# M058SAN_v1 register map
File version: 1.0
Registers are 32-bit, read-write, reset 0x0 unless marked. A register's access mark holds for its fields unless they carry their own. Offsets are from the block's base; [hi:lo] are bit positions; {n}, {i} and the like mark numbered series; 'fields as' and 'values as' point back to an identical list.

## I2C0 — I2C Register Map
Base 0x40020000
Same registers: I2C1 0x40120000
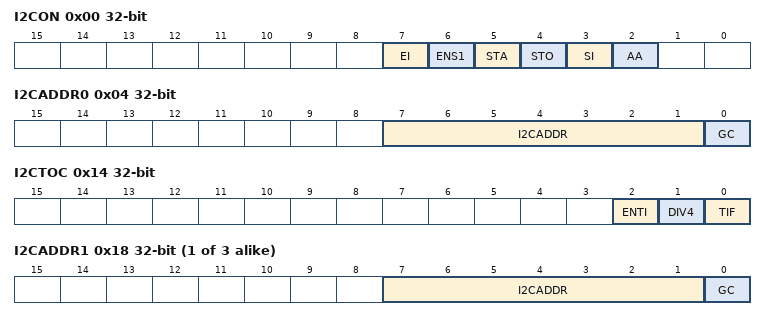
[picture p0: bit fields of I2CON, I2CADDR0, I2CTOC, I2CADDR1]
0x00 I2CON — I2C Control Register
  [7] EI — Enable Interrupt
    0=Disable I2C interrupt; 1=Enable I2C interrupt
  [6] ENS1 — I2C Controller Enable Bit
    0=Disable; 1=Enable
  [5] STA — I2C START Control Bit. Setting STA to logic 1 to enter master mode, the I2C hardware sends a START or repeat START condition to bus when the bus is free.
  [4] STO — I2C STOP Control Bit. In master mode, setting STO to transmit a STOP condition to bus then I2C hardware will check the bus condition if a STOP condition is detected this bit will be cleared by hardware automatically. In a slave mode, setting STO resets I2C hardware to the defined "not addressed" slave mode. This means it is NO LONGER in the slave receiver mode to receive data from the master transmit device.
  [3] SI — I2C Interrupt Flag. When a new I2C state is present in the I2CSTATUS register, the SI flag is set by hardware, and if bit EI (I2CON [7]) is set, the I2C interrupt is requested. SI must be cleared by software. Clear SI is by writing one to this bit.
  [2] AA — Assert Acknowledge Control Bit
0x04 I2CADDR0 — I2C slave Address Register0
  [7:1] I2CADDR — I2C Address Register. The content of this register is irrelevant when I2C is in master mode. In the slave mode, the seven most significant bits must be loaded with the MCU's own address. The I2C hardware will react if either of the address is matched.
  [0] GC — General Call Function
    0=Disable General Call Function; 1=Enable General Call Function
0x08 I2CDAT — I2C DATA Register
  [7:0] I2CDAT — I2C Data Register. Bit [7:0] is located with the 8-bit transferred data of I2C serial port.
0x0C I2CSTATUS ro reset 0xF8
  [7:0] I2CSTATUS — I2C Status Register. The status register of I2C:
0x10 I2CLK — I2C clock divided Register
  [7:0] I2CLK — I2C clock divided Register. Note: The minimum value of I2CLK is 4.
0x14 I2CTOC — I2C Time out control Register
  [2] ENTI — Time-out counter is enabled/disable. When Enable, the 14 bit time-out counter will start counting when SI is clear. Setting flag SI to high will reset counter and re-start up counting after SI is cleared.
    0=Disable; 1=Enable
  [1] DIV4 — Time-Out counter input clock is divided by 4. When Enable, The time-Out period is extend 4 times.
    0=Disable; 1=Enable
  [0] TIF — Time-Out Flag. This bit is set by H/W when I2C time-out happened and it can interrupt CPU if I2C interrupt enable bit (EI) is set to 1. S/W can write 1 to clear this bit.
{0x14+4i} I2CADDR{i} (i=1..3) — I2C slave Address Register{i}
  fields as I2CADDR0
{0x24+4i} I2CADM{i} (i=0..3) — I2C slave Address Mask Register{i}
  [7:1] I2CADMx — I2C Address Mask register. I2C bus controllers support multiple address recognition with four address mask register. When the bit in the address mask register is set to one, it means the received corresponding address bit is don't-care. If the bit is set to zero, that means the received corresponding register bit should be exact the same as address register.
    0=Mask disable (the received corresponding register bit should be exact the same as address register.); 1=Mask enable (the received corresponding address bit is don't care.)
0x3C I2CWKUPCON — I2C Wake Up Control Register
  [0] WKUPEN — I2C Wakeup Function Enable
    0=Disable I2C wake up function; 1=Enable I2C wake up function
0x40 I2CWKUPSTS ro — I2C Wake Up Status Register
  [0] WKUPIF — I2C Wake Up Interrupt Flag. When chip is waked up from power down mode by I2C, this bit is set to 1. Software can write 1 to clear this bit

## WDT — WDT Register Map
Base 0x40004000
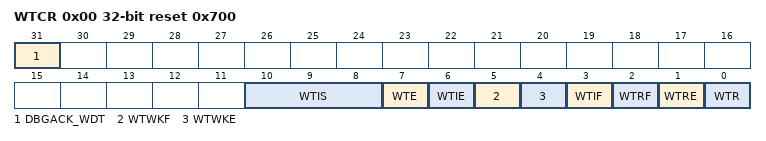
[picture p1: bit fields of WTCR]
0x00 WTCR reset 0x700 — Watchdog Timer Control Register
  [31] DBGACK_WDT — ICE debug mode acknowledge Disable (write-protected). Watchdog Timer counter will keep going no matter ICE debug mode acknowledged or not.
    0=ICE debug mode acknowledgement effects Watchdog Timer counting; 1=ICE debug mode acknowledgement disabled
  [10:8] WTIS — Watchdog Timer Interval Select (write protection bits)
  [7] WTE — Watchdog Timer Enable (write protection bits)
    0=Disable the Watchdog timer (This action will reset the internal counter); 1=Enable the Watchdog timer
  [6] WTIE — Watchdog Timer Interrupt Enable (write protection bits)
    0=Disable the Watchdog timer interrupt; 1=Enable the Watchdog timer interrupt
  [5] WTWKF — Watchdog Timer Wake-up Flag. If Watchdog timer causes chip wakes up from power down mode, this bit will be set to high. It must be cleared by software with a write 1 to this bit.
    0=Watchdog timer does not cause chip wake-up; 1=Chip wake-up from idle or power down mode by Watchdog timeout
  [4] WTWKE — Watchdog Timer Wake-up Function Enable bit (write-protection bit). Note: Chip can wake-up by WDT only if WDT clock source select RC10K
    0=Disable Watchdog timer wake-up chip function; 1=Enable the Wake-up function that Watchdog timer timeout can wake-up chip from power down mode
  [3] WTIF — Watchdog Timer Interrupt Flag. When watchdog timeout, the hardware will set this bit to indicate that the Watchdog timer interrupt has occurred. Note: This bit is cleared by writing 1 to this bit.
    0=Watchdog timer interrupt did not occur; 1=Watchdog timer interrupt occurs
  [2] WTRF — Watchdog Timer Reset Flag. When the Watchdog timer initiates a reset, the hardware will set this bit. This flag can be read by software to determine the source of reset. Software is responsible to clear it manually by writing 1 to it. If WTRE is disabled, then the Watchdog timer has no effect on this bit. Note: Write 1 to clear this bit to zero.
    0=Watchdog timer reset did not occur; 1=Watchdog timer reset occurs
  [1] WTRE — Watchdog Timer Reset Enable. Setting this bit will enable the Watchdog timer reset function.
    0=Disable Watchdog timer reset function; 1=Enable Watchdog timer reset function
  [0] WTR — Clear Watchdog Timer (write-protection bit). Set this bit will clear the Watchdog timer. Note: This bit will be auto cleared by hardware
    0=Writing 0 to this bit has no effect; 1=Reset the contents of the Watchdog timer
